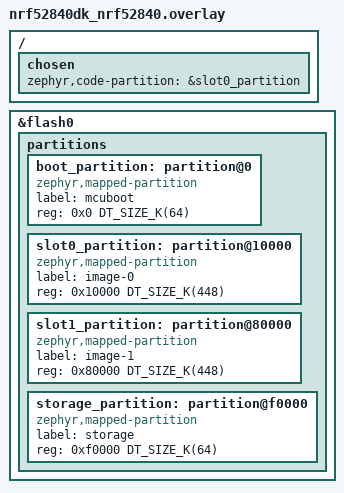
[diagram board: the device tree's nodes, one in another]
/*
 * Copyright (c) 2026 Nordic Semiconductor ASA
 *
 * SPDX-License-Identifier: LicenseRef-Nordic-5-Clause
 */

&flash0 {
	/delete-node/ partitions;

	partitions {
		ranges;
		#address-cells = <1>;
		#size-cells = <1>;

		boot_partition: partition@0 {
			compatible = "zephyr,mapped-partition";
			label = "mcuboot";
			reg = <0x0 DT_SIZE_K(64)>;
		};

		slot0_partition: partition@10000 {
			compatible = "zephyr,mapped-partition";
			label = "image-0";
			reg = <0x10000 DT_SIZE_K(448)>;
		};

		slot1_partition: partition@80000 {
			compatible = "zephyr,mapped-partition";
			label = "image-1";
			reg = <0x80000 DT_SIZE_K(448)>;
		};

		storage_partition: partition@f0000 {
			compatible = "zephyr,mapped-partition";
			label = "storage";
			reg = <0xf0000 DT_SIZE_K(64)>;
		};
	};
};

/ {
	chosen {
		zephyr,code-partition = &slot0_partition;
	};
};
